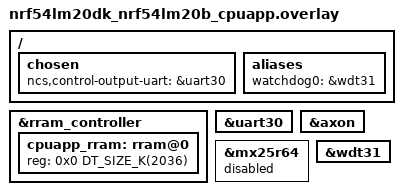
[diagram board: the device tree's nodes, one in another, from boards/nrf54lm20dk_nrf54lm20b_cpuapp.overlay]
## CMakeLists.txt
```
#
# Copyright (c) 2026 Nordic Semiconductor ASA
#
# SPDX-License-Identifier: LicenseRef-Nordic-5-Clause
#

cmake_minimum_required(VERSION 3.20.0)

find_package(Zephyr REQUIRED HINTS $ENV{ZEPHYR_BASE})
project(matter_switch)

# Enable GNU STD support.
include(${ZEPHYR_CONNECTEDHOMEIP_MODULE_DIR}/config/nrfconnect/app/enable-gnu-std.cmake)

# NORDIC SDK APP START

# Include all source files that are located in the Matter common directory.
include(${ZEPHYR_NRF_MODULE_DIR}/samples/matter/common/cmake/source_common.cmake)

# Include Data Model utils
include(${ZEPHYR_NRF_MODULE_DIR}/samples/matter/common/cmake/data_model.cmake)

include(${ZEPHYR_NRF_MODULE_DIR}/samples/matter/common/cmake/zap_helpers.cmake)
ncs_get_zap_parent_dir(ZAP_PARENT_DIR)

set(MATTER_EDGEAI_COMMON_DIR ${CMAKE_CURRENT_SOURCE_DIR}/../matter_common)

target_include_directories(app PRIVATE
  src
  src/nrf_edgeai_generated
  src/switch
  src/edgeAI
  ${MATTER_EDGEAI_COMMON_DIR}
  ${ZAP_PARENT_DIR}
)

target_compile_options(app PRIVATE -Wno-deprecated-declarations)

target_sources(app PRIVATE
  src/main.cpp
  src/app_task.cpp
  src/nrf_edgeai_task.cpp

  src/switch/switch.cpp

  src/wakeword.c
  src/keyword.c
  src/models/wakeword/nrf_edgeai_generated/nrf_edgeai_user_model.c
  src/models/kws/nrf_edgeai_generated/nrf_edgeai_user_model.c

  ${MATTER_EDGEAI_COMMON_DIR}/dimming_effect.cpp
  ${MATTER_EDGEAI_COMMON_DIR}/dmic.c
)

target_sources_ifdef(CONFIG_SWITCH_SHELL app PRIVATE src/switch/shell_commands.cpp)
target_sources_ifdef(CONFIG_GENERIC_SWITCH app PRIVATE src/switch/generic_switch.cpp)
target_sources_ifdef(CONFIG_LIGHT_SWITCH app PRIVATE src/switch/light_switch.cpp)
target_sources_ifdef(CONFIG_LIGHT_SWITCH app PRIVATE ${ZEPHYR_NRF_MODULE_DIR}/samples/matter/common/src/binding/binding_handler.cpp)

ncs_configure_data_model()
```

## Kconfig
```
#
# Copyright (c) 2026 Nordic Semiconductor ASA
#
# SPDX-License-Identifier: LicenseRef-Nordic-5-Clause
#

rsource "../matter_common/Kconfig.edgeai"

menu "Matter Edge AI Switch"

choice SWITCH_TYPE
	prompt "Matter Switch Type"
	default GENERIC_SWITCH
	help
	  Choose the type of switch to act as.

config LIGHT_SWITCH
	bool "Act as a Light Switch"
	help
	  Act as a Light Switch, which uses client application clusters (for example, Level Control) and bindings to send commands to the server clusters.

config GENERIC_SWITCH
	bool "Act as a Generic Switch"
	help
	  Act as a Generic Switch, which implements the Momentary Switch (`MS`) and Momentary Switch Release (`MSR`) features.

endchoice

config SWITCH_ENDPOINT_ID
	int "Switch Endpoint ID"
	default 1
	help
	  Endpoint ID for the switch.

config SWITCH_SHELL
	bool "Switch Shell"
	depends on CHIP_LIB_SHELL
	depends on !GENERIC_SWITCH # Currently only Light Switch supports shell commands
	help
	  Enable the Switch Shell.

if LIGHT_SWITCH

config NCS_SAMPLE_MATTER_ZAP_FILE_PATH
	default "${APPLICATION_CONFIG_DIR}/src/light_switch_zap/light_switch.zap"

endif # LIGHT_SWITCH

if GENERIC_SWITCH

config NCS_SAMPLE_MATTER_ZAP_FILE_PATH
	default "${APPLICATION_CONFIG_DIR}/src/generic_switch_zap/generic_switch.zap"

endif # GENERIC_SWITCH

config SWITCH_THREAD_STACK_SIZE
	int "Edge AI Switch thread stack size"
	default 6144
	help
	  Stack size for switch thread.

config SWITCH_THREAD_PRIORITY
	int "Edge AI Switch thread priority"
	default 8
	help
	  Preemptible thread priority.

config WW_PROBABILITY_THRESHOLD
	int "Wakeword probability threshold"
	range 0 1000
	default 990
	help
	   Probability threshold for wakeword detection model. The value is expressed in units of
	   1/1000.

config WW_HISTORY_SIZE
	int "Size of wakeword predictions history"
	range 1 32
	default 20
	help
	  Size of history of previous results from wakeword detection model. Each entry corresponds
	  to 30 milliseconds of past audio.

config WW_COUNT_THRESHOLD
	int "Threshold for wakeword detection from predictions history"
	range 1 WW_HISTORY_SIZE
	default 15
	help
	  Number of predictions above threshold in predictions history required to confirm wakeword
	  detection.

config KW_DETECTION_TIMEOUT_S
	int "Timeout for keyword detection in seconds"
	range 1 60
	default 5
	help
	  Timeout for keyword detection in seconds after recognizing the wakeword.

endmenu

# Sample configuration used for Thread networking
if OPENTHREAD

choice OPENTHREAD_NORDIC_LIBRARY_CONFIGURATION
	default OPENTHREAD_NORDIC_LIBRARY_MTD
endchoice

choice OPENTHREAD_DEVICE_TYPE
	default OPENTHREAD_MTD
endchoice

config CHIP_ENABLE_ICD_SUPPORT
	default y

# Reduce Thread TX output power to 0 dBm for SED device
config OPENTHREAD_DEFAULT_TX_POWER
	default 0

endif # OPENTHREAD

source "$(ZEPHYR_CONNECTEDHOMEIP_MODULE_DIR)/config/nrfconnect/chip-module/Kconfig.features"
source "$(ZEPHYR_CONNECTEDHOMEIP_MODULE_DIR)/config/nrfconnect/chip-module/Kconfig.defaults"
source "$(ZEPHYR_NRF_MODULE_DIR)/samples/matter/common/src/Kconfig"
source "Kconfig.zephyr"
```

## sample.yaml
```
sample:
  description: Matter Switch application
  name: Matter Switch

common:
  sysbuild: true
  build_only: true
  tags:
    - ci_build
    - sysbuild

tests:
  applications.matter_switch.generic_switch_debug_dmic_adafruit:
    extra_args:
      - CONFIG_GENERIC_SWITCH=y
      - EXTRA_DTC_OVERLAY_FILE=boards/dmic_adafruit.dtsi
    platform_allow:
      - nrf54lm20dk/nrf54lm20b/cpuapp
    integration_platforms:
      - nrf54lm20dk/nrf54lm20b/cpuapp
  applications.matter_switch.generic_switch_debug_dmic_low_power:
    extra_args:
      - CONFIG_GENERIC_SWITCH=y
      - EXTRA_DTC_OVERLAY_FILE=boards/dmic_low_power.dtsi
    platform_allow:
      - nrf54lm20dk/nrf54lm20b/cpuapp
    integration_platforms:
      - nrf54lm20dk/nrf54lm20b/cpuapp
  applications.matter_switch.light_switch_debug_dmic_adafruit:
    extra_args:
      - CONFIG_LIGHT_SWITCH=y
      - EXTRA_DTC_OVERLAY_FILE=boards/dmic_adafruit.dtsi
    platform_allow:
      - nrf54lm20dk/nrf54lm20b/cpuapp
    integration_platforms:
      - nrf54lm20dk/nrf54lm20b/cpuapp
  applications.matter_switch.light_switch_debug_dmic_low_power:
    extra_args:
      - CONFIG_LIGHT_SWITCH=y
      - EXTRA_DTC_OVERLAY_FILE=boards/dmic_low_power.dtsi
    platform_allow:
      - nrf54lm20dk/nrf54lm20b/cpuapp
    integration_platforms:
      - nrf54lm20dk/nrf54lm20b/cpuapp
```

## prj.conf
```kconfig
#
# Copyright (c) 2026 Nordic Semiconductor
#
# SPDX-License-Identifier: LicenseRef-Nordic-5-Clause
#

# Enable CHIP
CONFIG_CHIP=y
CONFIG_CHIP_PROJECT_CONFIG="src/chip_project_config.h"
CONFIG_CHIP_DEVICE_PRODUCT_NAME="Matter AI Switch"

# 32772 == 0x8004 (example matter_switch-app)
CONFIG_CHIP_DEVICE_PRODUCT_ID=32772
CONFIG_STD_CPP17=y

# Enable Matter extended announcement and increase duration to 1 hour.
CONFIG_CHIP_BLE_EXT_ADVERTISING=y
CONFIG_CHIP_BLE_ADVERTISING_DURATION=60

# Add support for LEDs and buttons on Nordic development kits
CONFIG_DK_LIBRARY=y

# Bluetooth Low Energy configuration
CONFIG_BT_DEVICE_NAME="MatterAISwitch"

# Enable Matter pairing automatically on application start.
CONFIG_CHIP_ENABLE_PAIRING_AUTOSTART=y

# Suspend devices when the CPU goes into sleep
CONFIG_PM_DEVICE=y

# Other settings
CONFIG_THREAD_NAME=y
CONFIG_MPU_STACK_GUARD=y

CONFIG_SYSTEM_WORKQUEUE_STACK_SIZE=4096

# Memory: k_malloc pool + Matter chip heap are static (.bss) and sit before the Newlib arena
# (RAM from _end to top of SRAM). Edge AI uses malloc(); if that arena is too small, the first
# stdio/C++ lock init hits: "recursive lock allocation failed" in libc-hooks.c.
CONFIG_MAIN_STACK_SIZE=10240
CONFIG_COMMON_LIBC_MALLOC_ARENA_SIZE=-1
CONFIG_NEWLIB_LIBC_MIN_REQUIRED_HEAP_SIZE=40960
CONFIG_HEAP_MEM_POOL_SIZE=24576
CONFIG_CHIP_MALLOC_SYS_HEAP_SIZE=40960
CONFIG_CHIP_SYSTEM_PACKETBUFFER_POOL_SIZE=24
CONFIG_CHIP_TASK_STACK_SIZE=12288
CONFIG_SWITCH_THREAD_STACK_SIZE=8192
CONFIG_SWITCH_THREAD_PRIORITY=0

CONFIG_RESET_ON_FATAL_ERROR=n
CONFIG_CHIP_LIB_SHELL=y
CONFIG_NCS_SAMPLE_MATTER_TEST_SHELL=y

# Reduce application size
CONFIG_USE_SEGGER_RTT=n
CONFIG_MATTER_LOG_LEVEL_INF=y
CONFIG_CHIP_APP_LOG_LEVEL=3

# Enable Factory Data feature
CONFIG_CHIP_FACTORY_DATA=y
CONFIG_CHIP_FACTORY_DATA_BUILD=y

# nRF Edge AI
CONFIG_NRF_EDGEAI=y

# nRF Edge AI dependencies
CONFIG_NRF_AXON=y
CONFIG_NEWLIB_LIBC=y
CONFIG_FPU=y

# Size of interlayer buffer to fit model
CONFIG_NRF_AXON_INTERLAYER_BUFFER_SIZE=8192

# Size of psum buffer to fit model
CONFIG_NRF_AXON_PSUM_BUFFER_SIZE=0

# Enable sensor, button and LED libraries
CONFIG_GPIO=y
CONFIG_AUDIO=y
CONFIG_AUDIO_DMIC=y

# PWM-driven LED dimming on wakeword
CONFIG_PWM=y
```

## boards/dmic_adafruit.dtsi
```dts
/*
 * Copyright (c) 2026 Nordic Semiconductor ASA
 *
 * SPDX-License-Identifier: LicenseRef-Nordic-5-Clause
 */

&pinctrl {
	pdm20_default_alt: pdm20_default_alt {
		group1 {
			psels = <NRF_PSEL(PDM_CLK, 1, 4)>,
				<NRF_PSEL(PDM_DIN, 1, 5)>;
		};
	};
};

dmic_dev: &pdm20 {
	status = "okay";
	pinctrl-0 = <&pdm20_default_alt>;
	pinctrl-names = "default";
	clock-source = "PCLK32M";
	queue-size = <12>;
};
```

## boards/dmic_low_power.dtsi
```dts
/*
 * Copyright (c) 2026 Nordic Semiconductor ASA
 *
 * SPDX-License-Identifier: LicenseRef-Nordic-5-Clause
 */

 &pinctrl {
	pdm20_default_alt: pdm20_default_alt {
		group1 {
			psels = <NRF_PSEL(PDM_CLK, 1, 12)>,
				<NRF_PSEL(PDM_DIN, 1, 8)>;
		};
	};
};

dmic_dev: &pdm20 {
	status = "okay";
	pinctrl-0 = <&pdm20_default_alt>;
	pinctrl-names = "default";
	clock-source = "PCLK32M_HFXO";
	queue-size = <16>;
};
```

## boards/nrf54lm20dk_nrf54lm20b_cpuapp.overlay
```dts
/*
 * Copyright (c) 2026 Nordic Semiconductor ASA
 *
 * SPDX-License-Identifier: LicenseRef-Nordic-5-Clause
 */

/ {
	chosen {
		ncs,control-output-uart = &uart30;
	};

	aliases {
		/* Use watchdog wdt31 as the application watchdog */
		watchdog0 = &wdt31;
	};
};

&rram_controller {
	cpuapp_rram: rram@0 {
		reg = <0x0 DT_SIZE_K(2036)>;
		ranges = <0x0 0x0 DT_SIZE_K(2036)>;
	};
};

&uart30 {
	status = "okay";
};

&axon {
	status = "okay";
};

&mx25r64 {
	status = "disabled";
};

&wdt31 {
	status = "okay";
};
```

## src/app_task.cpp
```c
/*
 * Copyright (c) 2021 Nordic Semiconductor ASA
 *
 * SPDX-License-Identifier: LicenseRef-Nordic-5-Clause
 */

#include "app_task.h"

#include "app/matter_init.h"
#include "app/task_executor.h"
#include "board/board.h"
#include "lib/core/CHIPError.h"
#include "clusters/identify.h"
#include "switch.h"

#include "nrf_edgeai_task.h"

#include <setup_payload/OnboardingCodesUtil.h>

#include <app-common/zap-generated/attributes/Accessors.h>

#include <zephyr/kernel.h>
#include <zephyr/logging/log.h>

LOG_MODULE_DECLARE(app, CONFIG_CHIP_APP_LOG_LEVEL);

using namespace ::chip;
using namespace ::chip::app;
using namespace ::chip::app::Clusters;
using namespace ::chip::app::Clusters::OnOff;
using namespace ::chip::DeviceLayer;

K_SEM_DEFINE(gMatterStartedSem, 0, 1);

#define APPLICATION_BUTTON_MASK DK_BTN2_MSK

namespace
{
Nrf::Matter::IdentifyCluster sIdentifyCluster(Nrf::Matter::GetSwitch().GetSwitchEndpointId());

void ButtonEventHandler(Nrf::ButtonState state, Nrf::ButtonMask hasChanged)
{
	if ((APPLICATION_BUTTON_MASK & state & hasChanged)) {
		Nrf::Matter::GetSwitch().InitiateActionSwitch(::Switch::Action::Toggle);
	}
}

void matter_app_event_handler(const chip::DeviceLayer::ChipDeviceEvent *event, intptr_t arg)
{
	(void)arg;

	switch (event->Type) {
	case chip::DeviceLayer::DeviceEventType::kServerReady:
		// Enable Edge AI task when Matter server is ready
		EdgeAITask::Instance().Enable();
		k_sem_give(&gMatterStartedSem);
		break;
	case chip::DeviceLayer::DeviceEventType::kCHIPoBLEConnectionEstablished:
		// Disable Edge AI task when commissioning is in progress
		EdgeAITask::Instance().Disable();
		break;
	default:
		break;
	}
}
} // namespace

CHIP_ERROR AppTask::Init()
{
	ReturnErrorOnFailure(
		Nrf::Matter::PrepareServer(Nrf::Matter::InitData{.mPostServerInitClbk = [] {
			Nrf::Matter::GetSwitch().Init();
			return CHIP_NO_ERROR;
		}}));

	if (!Nrf::GetBoard().Init(ButtonEventHandler)) {
		LOG_ERR("User interface initialization failed.");
		return CHIP_ERROR_INCORRECT_STATE;
	}

	ReturnErrorOnFailure(Nrf::Matter::RegisterEventHandler(matter_app_event_handler, 0));
	ReturnErrorOnFailure(
		Nrf::Matter::RegisterEventHandler(Nrf::Board::DefaultMatterEventHandler, 0));

	ReturnErrorOnFailure(sIdentifyCluster.Init());

	return Nrf::Matter::StartServer();
}

CHIP_ERROR AppTask::StartApp()
{
	ReturnErrorOnFailure(Init());

	ReturnErrorOnFailure(EdgeAITask::Instance().Start());

	while (true) {
		Nrf::DispatchNextTask();
	}

	return CHIP_NO_ERROR;
}

void MatterPostAttributeChangeCallback(const chip::app::ConcreteAttributePath &attributePath,
				       uint8_t type, uint16_t size, uint8_t *value)
{
	ClusterId clusterId = attributePath.mClusterId;
	AttributeId attributeId = attributePath.mAttributeId;

	if (clusterId == OnOff::Id && attributeId == OnOff::Attributes::OnOff::Id) {
		LOG_INF("Cluster OnOff: attribute OnOff set to %" PRIu8 "", *value);

		bool value_invert = !*value;

		Nrf::GetBoard().GetLED(Nrf::DeviceLeds::LED2).Set(value_invert);
	}
}
```

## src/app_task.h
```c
/*
 * Copyright (c) 2026 Nordic Semiconductor ASA
 *
 * SPDX-License-Identifier: LicenseRef-Nordic-5-Clause
 */

#pragma once

#include <platform/CHIPDeviceLayer.h>
#include <zephyr/kernel.h>
#include "lib/support/CodeUtils.h"

extern struct k_sem gMatterStartedSem;

class AppTask
{
      public:
	static AppTask &Instance()
	{
		static AppTask sAppTask;
		return sAppTask;
	};

	CHIP_ERROR StartApp();

      private:
	CHIP_ERROR Init();
};
```

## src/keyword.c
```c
/*
 * Copyright (c) 2026 Nordic Semiconductor ASA
 *
 * SPDX-License-Identifier: LicenseRef-Nordic-5-Clause
 */

#include "keyword.h"

#include <string.h>

#include <zephyr/logging/log.h>
#include <nrf_edgeai/nrf_edgeai.h>
#include <nrf_edgeai/rt/nrf_edgeai_runtime_aux.h>

#include "dmic.h"
#include "models/kws/nrf_edgeai_generated/nrf_edgeai_user_model.h"

LOG_MODULE_DECLARE(kw, CONFIG_CHIP_APP_LOG_LEVEL);

const keyword_class_cfg_t KEYWORD_CLASSES_CFG[] = {
	[KEYWORD_OFF] = {.name = "OFF", .count_needed = 2, .threshold_percent = 0},
	[KEYWORD_ON] = {.name = "ON", .count_needed = 2, .threshold_percent = 0},
	[KEYWORD_OTHER] = {.name = "OTHER", .count_needed = 4, .threshold_percent = 0},
	[KEYWORD_SILENCE] = {.name = "SILENCE", .count_needed = 4, .threshold_percent = 0},
	[KEYWORD_SWITCH] = {.name = "SWITCH", .count_needed = 2, .threshold_percent = 0},
};

static nrf_edgeai_t *kw_model;

static keyword_runtime_ctx_t s_keyword_runtime_ctx;
static keyword_phrase_ctx_t s_keyword_phrase_ctx;

static void reset_keyword_detection_state(void);
static bool is_keyword_command_component(uint16_t predicted_class);
static bool is_keyword_phrase_first_word(uint16_t predicted_class);
static const keyword_class_cfg_t *get_keyword_class_cfg(uint16_t predicted_class);
static bool is_keyword_probability_above_threshold(uint16_t predicted_class, float probability);
static bool try_detect_keyword_command(uint16_t predicted_class, float probability,
				       const char **pp_first_keyword_name,
				       const char **pp_second_keyword_name,
				       bool *p_has_second_keyword, uint8_t *p_average_probability);

int kw_init(void)
{
	kw_model = nrf_edgeai_user_model_kws();
	__ASSERT_NO_MSG(kw_model);

	nrf_edgeai_err_t err = nrf_edgeai_init(kw_model);

	if (err) {
		LOG_ERR("Model initialization failed (err %d)", err);
		return -ENOENT;
	}

	return 0;
}

int kw_process(uint8_t *const audio_buffer, const uint16_t num_samples, uint16_t *const kw_class)
{
	__ASSERT_NO_MSG(kw_model);
	__ASSERT_NO_MSG(audio_buffer);
	__ASSERT_NO_MSG(kw_class);

	nrf_edgeai_err_t err;
	err = nrf_edgeai_feed_inputs(kw_model, audio_buffer, num_samples);

	free_dmic_buffer(audio_buffer);

	if (err == NRF_EDGEAI_ERR_INPROGRESS) {
		/* Skip inference, not enough data. */
		return -EBUSY;
	} else if (err) {
		LOG_ERR("Failed to feed inputs (err %d)", err);
		return -EPERM;
	}

	err = nrf_edgeai_run_inference(kw_model);

	if (err == NRF_EDGEAI_ERR_INPROGRESS) {
		/* Skip output extraction, not enough data. */
		return -EBUSY;
	} else if (err) {
		LOG_ERR("Failed to run inference (err %d)", err);
		return -EPERM;
	}
	// return 1;
	/* KWS model may have more output classes (e.g. 12) than this app enum (KEYWORDS_cnt). */
	const uint16_t raw_class = kw_model->decoded_output.classif.predicted_class;
	const uint16_t n_out = nrf_edgeai_model_outputs_num(kw_model);

	if (n_out == 0U || raw_class >= n_out) {
		*kw_class = KEYWORD_OTHER;
		return 0;
	}
	flt32_t probability = kw_model->decoded_output.classif.probabilities.p_f32[raw_class];
	*kw_class = (raw_class < (uint16_t)KEYWORDS_cnt) ? raw_class : KEYWORD_OTHER;

	const char *first_keyword_name = NULL;
	const char *second_keyword_name = NULL;
	bool has_second_keyword = false;
	uint8_t average_probability_pct = 0;

	if (try_detect_keyword_command(*kw_class, probability, &first_keyword_name,
				       &second_keyword_name, &has_second_keyword,
				       &average_probability_pct)) {
		/* *kw_class still holds the class that completed the command (caller maps to
		 * action). */
		LOG_INF("Keyword detected: %s, %d %%\n", first_keyword_name,
			average_probability_pct);
		reset_keyword_detection_state();
		return 1;
	}
	*kw_class = KEYWORD_OTHER;
	return 0;
}

void kw_reset_model(void)
{
	nrf_edgeai_model_axon_init_persistent_vars(kw_model);
	reset_keyword_detection_state();
}

static void reset_keyword_detection_state(void)
{
	memset(&s_keyword_runtime_ctx, 0, sizeof(s_keyword_runtime_ctx));
	memset(&s_keyword_phrase_ctx, 0, sizeof(s_keyword_phrase_ctx));
}

static bool is_keyword_command_component(uint16_t predicted_class)
{
	return (predicted_class < KEYWORDS_cnt) && (predicted_class != KEYWORD_OTHER) &&
	       (predicted_class != KEYWORD_SILENCE);
}

static bool is_keyword_phrase_first_word(uint16_t predicted_class)
{
	return (predicted_class == KEYWORD_ON) || (predicted_class == KEYWORD_OFF) ||
	       (predicted_class == KEYWORD_SWITCH);
}

static const keyword_class_cfg_t *get_keyword_class_cfg(uint16_t predicted_class)
{
	if (predicted_class >= KEYWORDS_cnt) {
		return &KEYWORD_CLASSES_CFG[KEYWORD_OTHER];
	}
	return &KEYWORD_CLASSES_CFG[predicted_class];
}

static bool is_keyword_probability_above_threshold(uint16_t predicted_class, flt32_t probability)
{
	const keyword_class_cfg_t *p_class_cfg = get_keyword_class_cfg(predicted_class);

	if (p_class_cfg->threshold_percent == 0) {
		return true;
	}

	return (probability * 100.0f) >= (flt32_t)p_class_cfg->threshold_percent;
}

static bool try_detect_keyword_command(uint16_t predicted_class, flt32_t probability,
				       const char **pp_first_keyword_name,
				       const char **pp_second_keyword_name,
				       bool *p_has_second_keyword, uint8_t *p_average_probability)
{
	const keyword_class_cfg_t *p_class_cfg = get_keyword_class_cfg(predicted_class);
	const bool is_command_component = is_keyword_command_component(predicted_class);
	const bool passes_threshold =
		is_command_component &&
		is_keyword_probability_above_threshold(predicted_class, probability);

	*pp_first_keyword_name = NULL;
	*pp_second_keyword_name = NULL;
	*p_has_second_keyword = false;
	*p_average_probability = 0;

	const uint32_t now_ms = k_uptime_get_32();

	if (s_keyword_runtime_ctx.wait_for_class_change) {
		if (predicted_class == s_keyword_runtime_ctx.blocked_class) {
			return false;
		}

		s_keyword_runtime_ctx.wait_for_class_change = false;
	}

	if (!passes_threshold) {
		if (is_command_component) {
			/* A low-confidence keyword should break the current confirmation streak. */
			s_keyword_runtime_ctx.has_active_class = false;
			s_keyword_runtime_ctx.count = 0;
			s_keyword_runtime_ctx.average_probability = 0;
		}

		if ((s_keyword_runtime_ctx.non_keyword_count == 0) ||
		    (s_keyword_runtime_ctx.non_keyword_class != predicted_class)) {
			s_keyword_runtime_ctx.non_keyword_class = predicted_class;
			s_keyword_runtime_ctx.non_keyword_count = 0;
		}

		s_keyword_runtime_ctx.non_keyword_count++;

		if (s_keyword_phrase_ctx.has_first_keyword &&
		    (s_keyword_runtime_ctx.non_keyword_count < p_class_cfg->count_needed)) {
			/* Keep the first word alive across short OTHER/SILENCE gaps. */
			s_keyword_phrase_ctx.detected_at_ms = now_ms;
		}

		if (s_keyword_runtime_ctx.non_keyword_count >= p_class_cfg->count_needed) {
			s_keyword_runtime_ctx.has_active_class = false;
			s_keyword_runtime_ctx.count = 0;
			s_keyword_runtime_ctx.non_keyword_count = 0;
			s_keyword_runtime_ctx.non_keyword_class = 0;
			s_keyword_runtime_ctx.average_probability = 0;
		}

		return false;
	}

	s_keyword_runtime_ctx.non_keyword_count = 0;

	if (!s_keyword_runtime_ctx.has_active_class ||
	    (predicted_class != s_keyword_runtime_ctx.predicted_class)) {
		s_keyword_runtime_ctx.has_active_class = true;
		s_keyword_runtime_ctx.predicted_class = predicted_class;
		s_keyword_runtime_ctx.count = 0;
		s_keyword_runtime_ctx.non_keyword_count = 0;
		s_keyword_runtime_ctx.non_keyword_class = 0;
		s_keyword_runtime_ctx.average_probability = 0;
	}

	s_keyword_runtime_ctx.count++;
	s_keyword_runtime_ctx.average_probability +=
		(probability - s_keyword_runtime_ctx.average_probability) /
		s_keyword_runtime_ctx.count;

	if (s_keyword_phrase_ctx.has_first_keyword) {
		/* Any ongoing keyword activity extends the pairing window. */
		s_keyword_phrase_ctx.detected_at_ms = now_ms;
	}

#if !DEMO_FINAL_DETECTIONS_ONLY && PRINT_KEYWORD_CLASS_ACTIVITY
	printk("Keyword model class %s, count: %u \tprob : %0.3f\n",
	       get_keyword_class_cfg(s_keyword_runtime_ctx.predicted_class)->name,
	       (unsigned int)s_keyword_runtime_ctx.count,
	       s_keyword_runtime_ctx.average_probability);
#endif

	if (s_keyword_runtime_ctx.count < p_class_cfg->count_needed) {
		return false;
	}

	const flt32_t detected_probability = s_keyword_runtime_ctx.average_probability;

	s_keyword_runtime_ctx.has_active_class = false;
	s_keyword_runtime_ctx.count = 0;
	s_keyword_runtime_ctx.non_keyword_count = 0;
	s_keyword_runtime_ctx.non_keyword_class = 0;
	s_keyword_runtime_ctx.average_probability = 0;
	s_keyword_runtime_ctx.wait_for_class_change = true;
	s_keyword_runtime_ctx.blocked_class = predicted_class;

	/* `count_needed` is consecutive stable frames of this class, not a second spoken word. */
	if (is_keyword_phrase_first_word(predicted_class)) {
		unsigned avg_pct = (unsigned)(detected_probability * 100.0f + 0.5f);

		if (avg_pct > 100U) {
			avg_pct = 100U;
		}
		*pp_first_keyword_name = p_class_cfg->name;
		*pp_second_keyword_name = NULL;
		*p_has_second_keyword = false;
		*p_average_probability = (uint8_t)avg_pct;
		return true;
	}

	/* Unsupported combinations are ignored, but the confirmed first word stays active. */
	return false;
}
```

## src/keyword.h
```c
/*
 * Copyright (c) 2026 Nordic Semiconductor ASA
 *
 * SPDX-License-Identifier: LicenseRef-Nordic-5-Clause
 */

#ifndef __KEYWORD_H__
#define __KEYWORD_H__

#include <stdbool.h>
#include <stdint.h>
#include <stddef.h>

#ifdef __cplusplus
extern "C" {
#endif /* __cplusplus */

typedef struct {
	const char *name;
	size_t count_needed;
	uint8_t threshold_percent;
} keyword_class_cfg_t;

typedef struct {
	bool has_active_class;
	uint16_t predicted_class;
	size_t count;
	size_t non_keyword_count;
	uint16_t non_keyword_class;
	float average_probability;
	bool wait_for_class_change;
	uint16_t blocked_class;
} keyword_runtime_ctx_t;

typedef struct {
	bool has_first_keyword;
	uint16_t first_class;
	float first_probability;
	uint32_t detected_at_ms;
} keyword_phrase_ctx_t;

typedef enum keyword_labels_e {
	KEYWORD_OFF = 0,
	KEYWORD_ON = 1,
	KEYWORD_OTHER = 2,
	KEYWORD_SILENCE = 3,
	KEYWORD_SWITCH = 4,
	KEYWORDS_cnt
} keyword_labels_t;

int kw_init(void);
void kw_reset_model(void);
/**
 * @return 0 while still listening, 1 when a full keyword command is recognized (see @a kw_class),
 *         -EBUSY if more audio is needed, or another negative errno on error.
 */
int kw_process(uint8_t *const audio_buffer, const uint16_t num_samples, uint16_t *const kw_class);

extern const keyword_class_cfg_t KEYWORD_CLASSES_CFG[];
#ifdef __cplusplus
}
#endif /* __cplusplus */

#endif
```

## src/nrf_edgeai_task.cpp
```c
/*
 * Copyright (c) 2026 Nordic Semiconductor ASA
 *
 * SPDX-License-Identifier: LicenseRef-Nordic-5-Clause
 */

#include <errno.h>

#include <zephyr/audio/dmic.h>
#include <zephyr/device.h>
#include <zephyr/devicetree.h>
#include <zephyr/kernel.h>

#include "board/board.h"
#include "app/task_executor.h"

#include "platform/PlatformManager.h"
#include "pwm/pwm_device.h"
#include "dimming_effect.h"
#include <haly/nrfy_pdm.h>

#include "dmic.h"
#include "wakeword.h"
#include "keyword.h"
#include "nrf_edgeai_task.h"
#include "app_task.h"

#include <app-common/zap-generated/attributes/Accessors.h>
#include <platform/CHIPDeviceLayer.h>

#include <zephyr/logging/log.h>

LOG_MODULE_DECLARE(app, CONFIG_CHIP_APP_LOG_LEVEL);

using namespace ::chip;
using namespace ::chip::app;
using namespace ::chip::app::Clusters;
using namespace ::chip::app::Clusters::OnOff;
using namespace ::chip::DeviceLayer;

namespace
{

enum detection_state_e {
	WAITING_FOR_WAKEWORD,
	WAITING_FOR_KEYWORDS,
};

const struct device *const dmic_dev = DEVICE_DT_GET(DT_NODELABEL(dmic_dev));
void switch_thread_fn();
K_THREAD_DEFINE(switch_thread_id, CONFIG_SWITCH_THREAD_STACK_SIZE, switch_thread_fn, NULL, NULL,
		NULL, CONFIG_SWITCH_THREAD_PRIORITY, K_FP_REGS, SYS_FOREVER_MS);
void switch_thread_fn()
{
	void *audio_buffer;
	size_t audio_buffer_size;
	const int32_t read_timeout = 100;
	int err = 0;
	uint32_t kws_start_time = 0;
	detection_state_e app_state = WAITING_FOR_WAKEWORD;
	uint16_t class_detected = KEYWORD_OTHER;

	if (dmic_init()) {
		LOG_ERR("Failed to initialize DMIC");
		return;
	}

	if (ww_init() != 0) {
		LOG_ERR("Failed to initialize wakeword detection");
		return;
	}

	if (kw_init() != 0) {
		LOG_ERR("Failed to initialize keyword detection");
		return;
	}

	if (Nrf::DimmingEffect::IsAvailable()) {
		Nrf::DimmingEffect::Config dim_cfg;

		dim_cfg.effect_timeout_s = CONFIG_KW_DETECTION_TIMEOUT_S;
		dim_cfg.blink_pairs_multiplier = 3;
		(void)Nrf::DimmingEffect::Init(dim_cfg);
	}

	LOG_INF("Edge AI Switch initialization completed, Waiting for Matter to Start");
	k_sem_take(&gMatterStartedSem, K_FOREVER);
	LOG_INF("Matter server is ready, starting Edge AI capture");

	if (dmic_trigger(dmic_dev, DMIC_TRIGGER_START) < 0) {
		LOG_ERR("Failed to start DMIC");
		return;
	}
	nrfy_pdm_gain_set(NRF_PDM20, 0x40, 0x40);

	LOG_INF("\n\nWaiting for wakeword...\n\n");

	while (true) {
		bool ww_detected = false;

		err = dmic_read(dmic_dev, 0, &audio_buffer, &audio_buffer_size, read_timeout);
		if (err != 0) {
			if (err == -EAGAIN || err == -EBUSY) {
				k_yield();
				continue;
			}
			LOG_WRN("DMIC read failed (err %d)", err);
			k_sleep(K_MSEC(1));
			continue;
		}

		if (!EdgeAITask::Instance().IsEnabled()) {
			free_dmic_buffer(audio_buffer);
			continue;
		}
		switch (app_state) {
		case WAITING_FOR_WAKEWORD: {
			/* ww_process feeds the model and returns the DMIC block to the slab. */
			err = ww_process(reinterpret_cast<uint8_t *>(audio_buffer),
					 audio_buffer_size / DMIC_SAMPLE_BYTES, &ww_detected);
			if (err == -EBUSY) {
				continue;
			} else if (err < 0) {
				LOG_ERR("Wakeword detection failed (err %d)", err);
			}

			if (ww_detected) {

				LOG_INF("wakeword detected, Looking for keywords");
				kw_reset_model();
				kws_start_time = k_uptime_get_32();
				app_state = WAITING_FOR_KEYWORDS;

				if (Nrf::DimmingEffect::IsAvailable()) {
					Nrf::DimmingEffect::RequestStartViaTimer();
				}
			}
			break;
		}
		case WAITING_FOR_KEYWORDS: {
			if (k_uptime_get_32() - kws_start_time >
			    CONFIG_KW_DETECTION_TIMEOUT_S * 1000) {
				ww_reset_model();
				app_state = WAITING_FOR_WAKEWORD;
				LOG_INF("\n\nWaiting for wakeword...\n\n");
				break;
			}

			const int kws =
				kw_process(reinterpret_cast<uint8_t *>(audio_buffer),
					   audio_buffer_size / DMIC_SAMPLE_BYTES, &class_detected);
			if (kws == -EBUSY) {
				continue;
			}
			if (kws < 0) {
				LOG_ERR("Keyword detection failed (err %d)", kws);
				break;
			}
			/* 0: keep listening; 1: full phrase recognized. */
			if (kws == 0) {
				break;
			}
			switch (class_detected) {
			case KEYWORD_OFF: {
				SystemLayer().ScheduleLambda([] {
					LOG_INF("Turning light off");
					Nrf::Matter::GetSwitch().InitiateActionSwitch(
						::Switch::Action::Off);
				});
				break;
			}
			case KEYWORD_ON: {
				SystemLayer().ScheduleLambda([] {
					LOG_INF("Turning light on");
					Nrf::Matter::GetSwitch().InitiateActionSwitch(
						::Switch::Action::On);
				});
				break;
			}
			case KEYWORD_SWITCH: {
				SystemLayer().ScheduleLambda([] {
					LOG_INF("Toggling the light");

					Nrf::Matter::GetSwitch().InitiateActionSwitch(
						::Switch::Action::Toggle);
				});
				break;
			}
			default: {
				LOG_DBG("Not a valid keyword (class %u)", class_detected);
			}
			}
			// k_thread_suspend(switch_thread_id);
			ww_reset_model();
			app_state = WAITING_FOR_WAKEWORD;
			LOG_INF("\n\nWaiting for wakeword...\n\n");
			Nrf::DimmingEffect::Stop();
			break;
		}
		}
	}
}

} // namespace

CHIP_ERROR EdgeAITask::Start()
{
	k_thread_start(switch_thread_id);
	return CHIP_NO_ERROR;
}

void EdgeAITask::Enable()
{
	LOG_INF("\n\nAI task Enabled\n\n");
	enabled.store(true, std::memory_order_release);
}

void EdgeAITask::Disable()
{
	enabled.store(false, std::memory_order_release);
	LOG_INF("\n\nEdge AI listening disabled\n\n");
}
```

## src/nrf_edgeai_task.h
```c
/*
 * Copyright (c) 2026 Nordic Semiconductor ASA
 *
 * SPDX-License-Identifier: LicenseRef-Nordic-5-Clause
 */

#pragma once

#include <atomic>

#include <platform/CHIPDeviceLayer.h>
#include "switch.h"

class EdgeAITask
{
      public:
	/**
	 * @brief Get the singleton instance of EdgeAITask.
	 *
	 * @return Reference to the EdgeAITask instance.
	 */
	static EdgeAITask &Instance()
	{
		static EdgeAITask sEdgeAITask;
		return sEdgeAITask;
	};

	/**
	 * @brief Start the Edge AI task thread.
	 *
	 * @return CHIP_ERROR indicating success or failure.
	 */
	CHIP_ERROR Start();

	/**
	 * @brief Enable the Edge AI task.
	 */
	void Enable();

	/**
	 * @brief Disable the Edge AI task.
	 */
	void Disable();

	/**
	 * @brief Check if the Edge AI task is enabled.
	 *
	 * @return true if enabled, false otherwise.
	 */
	bool IsEnabled() const
	{
		return enabled.load(std::memory_order_acquire);
	}

      private:
	/** @brief Flag indicating whether the Edge AI task is enabled (Matter thread vs. Edge AI
	 * thread). */
	std::atomic<bool> enabled{false};
};
```

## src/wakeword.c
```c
/*
 * Copyright (c) 2026 Nordic Semiconductor ASA
 *
 * SPDX-License-Identifier: LicenseRef-Nordic-5-Clause
 */

#include <stddef.h>
#include <stdint.h>

#include <zephyr/logging/log.h>
#include <nrf_edgeai/nrf_edgeai.h>
#include <nrf_edgeai/rt/nrf_edgeai_runtime_aux.h>

#include "dmic.h"
#include "wakeword.h"
#include "models/wakeword/nrf_edgeai_generated/nrf_edgeai_user_model.h"

LOG_MODULE_REGISTER(ww);

static nrf_edgeai_t *ww_model;

int ww_init(void)
{
	ww_model = nrf_edgeai_user_model_92652();
	__ASSERT_NO_MSG(ww_model);

	nrf_edgeai_err_t err = nrf_edgeai_init(ww_model);

	if (err) {
		LOG_ERR("Model initialization failed (err %d)", err);
		return -ENOENT;
	}

	return 0;
}

void ww_reset_model(void)
{
	nrf_edgeai_model_axon_init_persistent_vars(ww_model);
}

static bool ww_postprocess(void)
{
	static uint32_t ww_count;
	static uint32_t ww_history;

	const float ww_threshold = CONFIG_WW_PROBABILITY_THRESHOLD / 1000.f;

	const uint16_t predicted_class = ww_model->decoded_output.classif.predicted_class;
	const float class_probability =
		ww_model->decoded_output.classif.probabilities.p_f32[predicted_class];
	const bool ww_detected = class_probability > ww_threshold;

	const bool oldest_entry = (bool)(ww_history & BIT(CONFIG_WW_HISTORY_SIZE - 1));

	ww_count = ww_count + ww_detected - oldest_entry;
	ww_history = (ww_history << 1) | ww_detected;

	LOG_DBG("postprocess: count: %2u, probability: %f", ww_count, (double)class_probability);

	if (ww_count >= CONFIG_WW_COUNT_THRESHOLD) {
		ww_count = 0;
		ww_history = 0;

		return true;
	}

	return false;
}

int ww_process(uint8_t *const audio_buffer, const uint16_t num_samples, bool *const ww_detected)
{
	__ASSERT_NO_MSG(audio_buffer);
	__ASSERT_NO_MSG(ww_model);
	__ASSERT_NO_MSG(ww_detected);

	nrf_edgeai_err_t err;

	err = nrf_edgeai_feed_inputs(ww_model, audio_buffer, num_samples);
	free_dmic_buffer(audio_buffer);

	if (err == NRF_EDGEAI_ERR_INPROGRESS) {
		/* Skip inference, not enough data. */
		return -EBUSY;
	} else if (err) {
		LOG_ERR("Failed to feed inputs (err %d)", err);
		return -EPERM;
	}

	err = nrf_edgeai_run_inference(ww_model);
	if (err == NRF_EDGEAI_ERR_INPROGRESS) {
		/* Skip output extraction, not enough data. */
		return -EBUSY;
	} else if (err) {
		LOG_ERR("Failed to run inference (err %d)", err);
		return -EPERM;
	}

	*ww_detected = ww_postprocess();

	return 0;
}
```

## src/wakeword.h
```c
/*
 * Copyright (c) 2026 Nordic Semiconductor ASA
 *
 * SPDX-License-Identifier: LicenseRef-Nordic-5-Clause
 */

/**
 * @defgroup ww_kws Wakeword and Keyword Spotting application
 */

/**
 * @defgroup wakeword Wakeword model functions
 * @{
 * @ingroup ww_kws
 */

#ifndef __WAKEWORD_H__
#define __WAKEWORD_H__

#include <stdbool.h>
#include <stdint.h>

#ifdef __cplusplus
extern "C" {
#endif /* __cplusplus */

/**
 * @brief Initialize Wakeword model.
 *
 * @return Operation status, 0 for success.
 */
int ww_init(void);

void ww_reset_model(void);
/**
 * @brief Process audio data by Wakeword model.
 *
 * @param audio_buffer Buffer of audio samples from dmic_read. Function takes ownership of
 pointer.
 * @param num_samples Number of audio samples.
 * @param[out] ww_detected Result of wakeword detection. Valid if operation completed
 successfully.

 * @retval 0 Operation successful.
 * @retval -EPERM Operation failed on nRF Edge AI Lib level.
 * @retval -EBUSY Model needs more data.
 */
int ww_process(uint8_t *const audio_buffer, const uint16_t num_samples, bool *const ww_detected);

#ifdef __cplusplus
}
#endif /* __cplusplus */

#endif /* __WAKEWORD_H__ */

/**
 * @}
 */
```
